# STM32L496ZGT7P register map
File version: 1.0
Registers are 32-bit, access not given, reset 0x0 unless marked. A register's access mark holds for its fields unless they carry their own. Offsets are from the block's base; [hi:lo] are bit positions; {n}, {i} and the like mark numbered series.

## OPAMP
Base 0x40007800
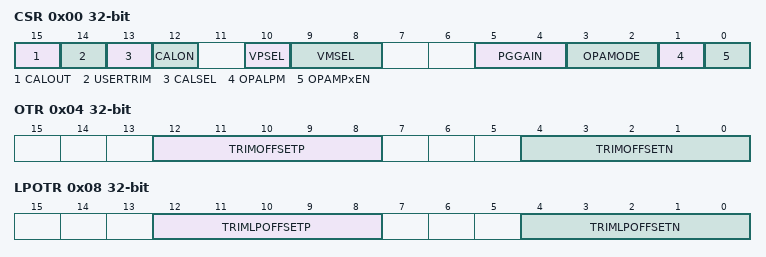
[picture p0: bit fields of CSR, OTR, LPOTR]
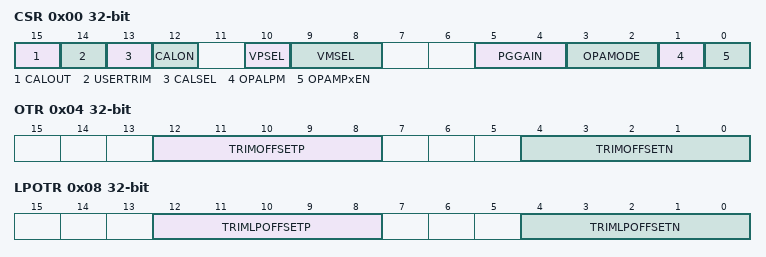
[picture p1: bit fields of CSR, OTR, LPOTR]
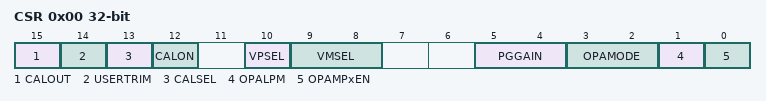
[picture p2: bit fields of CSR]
0x00 CSR
  [15] CALOUT, [14] USERTRIM, [13] CALSEL, [12] CALON, [10] VPSEL, [9:8] VMSEL, [5:4] PGGAIN, [3:2] OPAMODE, [1] OPALPM, [0] OPAMPxEN
0x04 OTR
  [12:8] TRIMOFFSETP, [4:0] TRIMOFFSETN
0x08 LPOTR
  [12:8] TRIMLPOFFSETP, [4:0] TRIMLPOFFSETN

## OPAMP1
Base 0x40007800
Same registers: OPAMP2 0x40007810
0x00 CSR
  [15] CALOUT, [14] USERTRIM, [13] CALSEL, [12] CALON, [10] VPSEL, [9:8] VMSEL, [5:4] PGGAIN, [3:2] OPAMODE, [1] OPALPM, [0] OPAMPxEN
0x04 OTR
  [12:8] TRIMOFFSETP, [4:0] TRIMOFFSETN
0x08 LPOTR
  [12:8] TRIMLPOFFSETP, [4:0] TRIMLPOFFSETN

## OPAMP12_COMMON
Base 0x40007800
0x00 CSR
  [15] CALOUT, [14] USERTRIM, [13] CALSEL, [12] CALON, [10] VPSEL, [9:8] VMSEL, [5:4] PGGAIN, [3:2] OPAMODE, [1] OPALPM, [0] OPAMPxEN

## LPTIM1
Base 0x40007C00
Same registers: LPTIM2 0x40009400
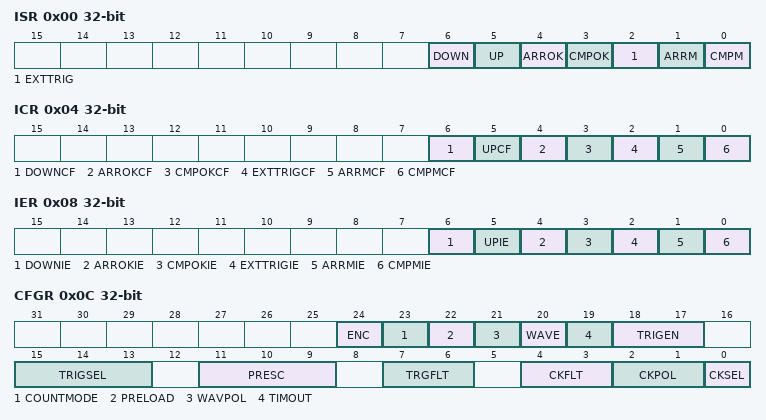
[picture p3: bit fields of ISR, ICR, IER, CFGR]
0x00 ISR
  [6] DOWN, [5] UP, [4] ARROK, [3] CMPOK, [2] EXTTRIG, [1] ARRM, [0] CMPM
0x04 ICR
  [6] DOWNCF, [5] UPCF, [4] ARROKCF, [3] CMPOKCF, [2] EXTTRIGCF, [1] ARRMCF, [0] CMPMCF
0x08 IER
  [6] DOWNIE, [5] UPIE, [4] ARROKIE, [3] CMPOKIE, [2] EXTTRIGIE, [1] ARRMIE, [0] CMPMIE
0x0C CFGR
  [24] ENC, [23] COUNTMODE, [22] PRELOAD, [21] WAVPOL, [20] WAVE, [19] TIMOUT, [18:17] TRIGEN, [15:13] TRIGSEL, [11:9] PRESC, [7:6] TRGFLT, [4:3] CKFLT, [2:1] CKPOL, [0] CKSEL
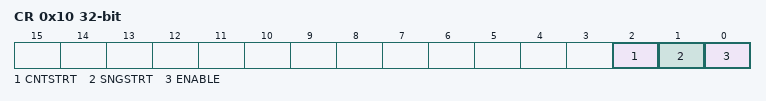
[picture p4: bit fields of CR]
0x10 CR
  [2] CNTSTRT, [1] SNGSTRT, [0] ENABLE
0x14 CMP
  [15:0] CMP
0x18 ARR
  [15:0] ARR
0x1C CNT
  [15:0] CNT
0x20 OR
  [1:0] OR

## SWPMI1
Base 0x40008800
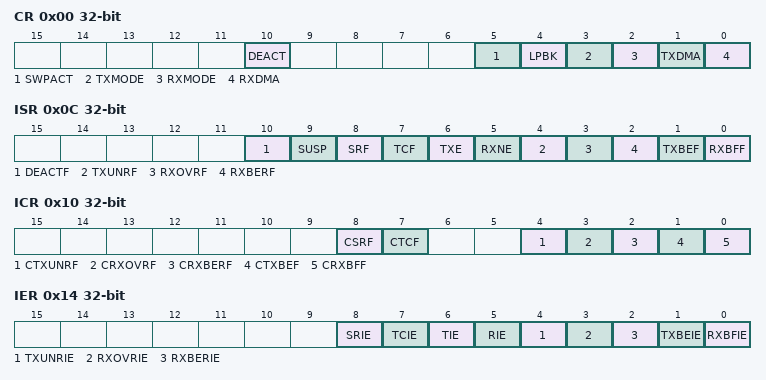
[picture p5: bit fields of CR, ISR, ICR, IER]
0x00 CR
  [10] DEACT, [5] SWPACT, [4] LPBK, [3] TXMODE, [2] RXMODE, [1] TXDMA, [0] RXDMA
0x04 BRR
  [5:0] BR
0x0C ISR
  [10] DEACTF, [9] SUSP, [8] SRF, [7] TCF, [6] TXE, [5] RXNE, [4] TXUNRF, [3] RXOVRF, [2] RXBERF, [1] TXBEF, [0] RXBFF
0x10 ICR
  [8] CSRF, [7] CTCF, [4] CTXUNRF, [3] CRXOVRF, [2] CRXBERF, [1] CTXBEF, [0] CRXBFF
0x14 IER
  [8] SRIE, [7] TCIE, [6] TIE, [5] RIE, [4] TXUNRIE, [3] RXOVRIE, [2] RXBERIE, [1] TXBEIE, [0] RXBFIE
0x18 RFL
  [1:0] RFL_0_1
0x1C TDR
  [31:0] TD
0x20 RDR
  [31:0] RD
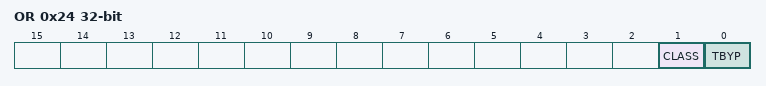
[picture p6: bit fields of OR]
0x24 OR
  [1] CLASS, [0] TBYP

## SYSCFG
Base 0x40010000
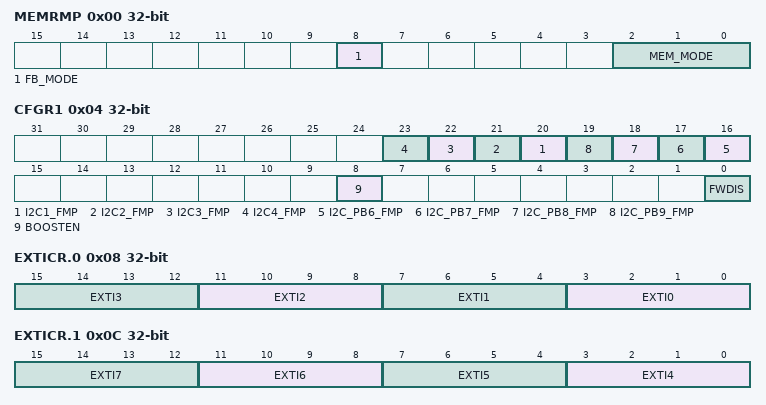
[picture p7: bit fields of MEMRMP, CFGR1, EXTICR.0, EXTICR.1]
0x00 MEMRMP
  [8] FB_MODE, [2:0] MEM_MODE
0x04 CFGR1
  [n+19] I2C{n}_FMP (n=1..4), [n+10] I2C_PB{n}_FMP (n=6..9), [8] BOOSTEN, [0] FWDIS
0x08 EXTICR.0
  [4n+3:4n] EXTI{n} (n=0..3)
0x0C EXTICR.1
  [4n-13:4n-16] EXTI{n} (n=4..7)
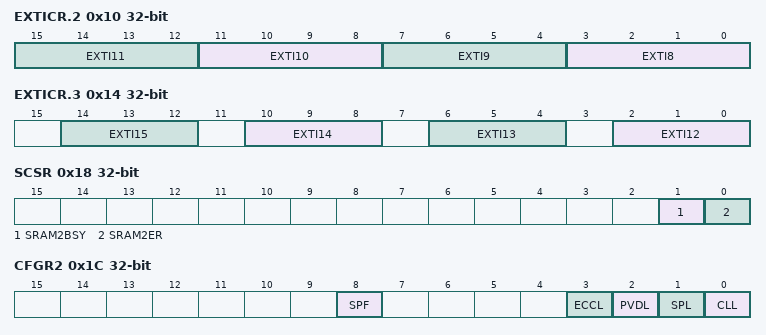
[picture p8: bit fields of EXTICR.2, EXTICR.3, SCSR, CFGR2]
0x10 EXTICR.2
  [4n-29:4n-32] EXTI{n} (n=8..11)
0x14 EXTICR.3
  [4n-46:4n-48] EXTI{n} (n=12..15)
0x18 SCSR
  [1] SRAM2BSY, [0] SRAM2ER
0x1C CFGR2
  [8] SPF, [3] ECCL, [2] PVDL, [1] SPL, [0] CLL
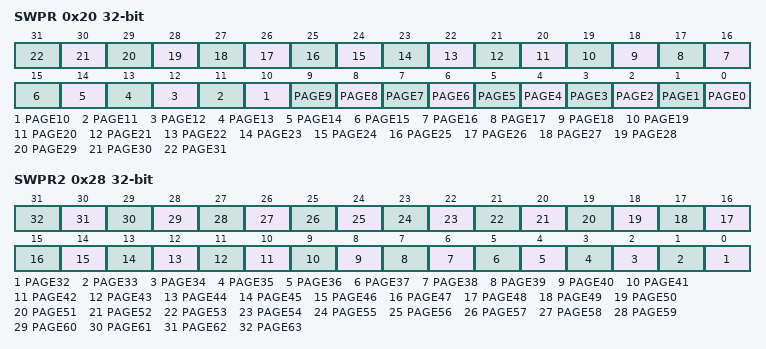
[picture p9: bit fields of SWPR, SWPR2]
0x20 SWPR
  [n] PAGE{n} (n=0..31)
0x24 SKR
  [7:0] KEY
0x28 SWPR2
  [n-32] PAGE{n} (n=32..63)

## VREFBUF
Base 0x40010030
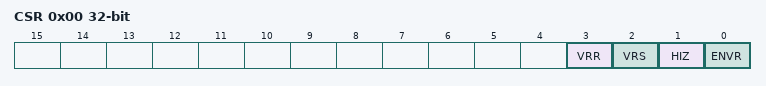
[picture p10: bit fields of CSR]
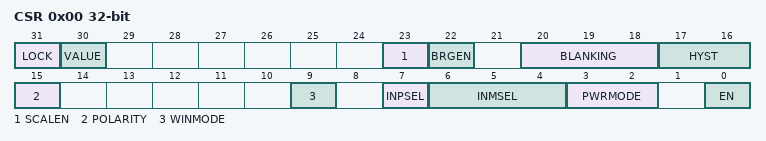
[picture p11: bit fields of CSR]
0x00 CSR
  [3] VRR, [2] VRS, [1] HIZ, [0] ENVR
0x04 CCR
  [5:0] TRIM

## COMP1
Base 0x40010200
Same registers: COMP2 0x40010204, COMP12_COMMON 0x40010204
0x00 CSR
  [31] LOCK, [30] VALUE, [23] SCALEN, [22] BRGEN, [20:18] BLANKING, [17:16] HYST, [15] POLARITY, [9] WINMODE, [7] INPSEL, [6:4] INMSEL, [3:2] PWRMODE, [0] EN

## EXTI
Base 0x40010400
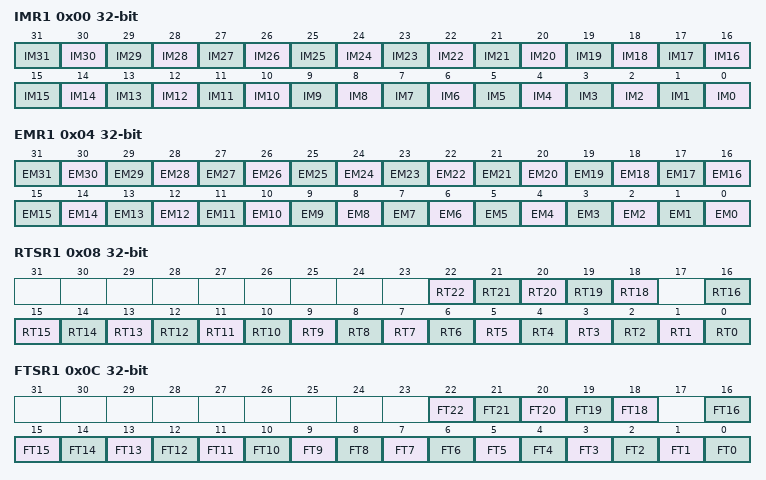
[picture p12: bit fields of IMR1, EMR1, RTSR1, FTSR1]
0x00 IMR1
  [n] IM{n} (n=0..31)
0x04 EMR1
  [n] EM{n} (n=0..31)
0x08 RTSR1
  [n] RT{n} (n=18..22), [n] RT{n} (n=0..16)
0x0C FTSR1
  [n] FT{n} (n=18..22), [n] FT{n} (n=0..16)
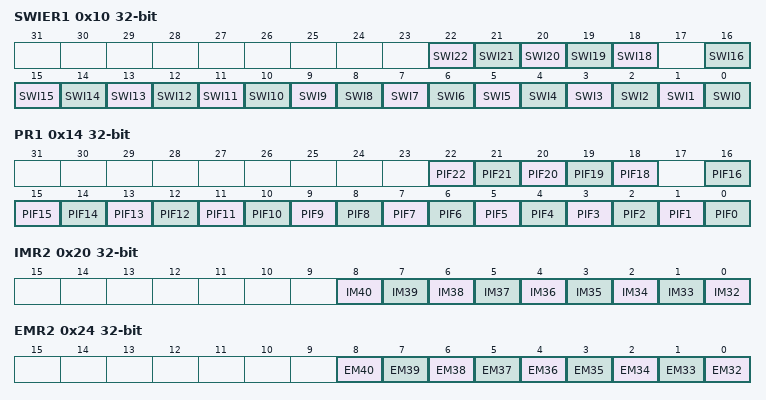
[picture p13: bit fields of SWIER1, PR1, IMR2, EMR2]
0x10 SWIER1
  [n] SWI{n} (n=18..22), [n] SWI{n} (n=0..16)
0x14 PR1
  [n] PIF{n} (n=18..22), [n] PIF{n} (n=0..16)
0x20 IMR2
  [n-32] IM{n} (n=32..40)
0x24 EMR2
  [n-32] EM{n} (n=32..40)
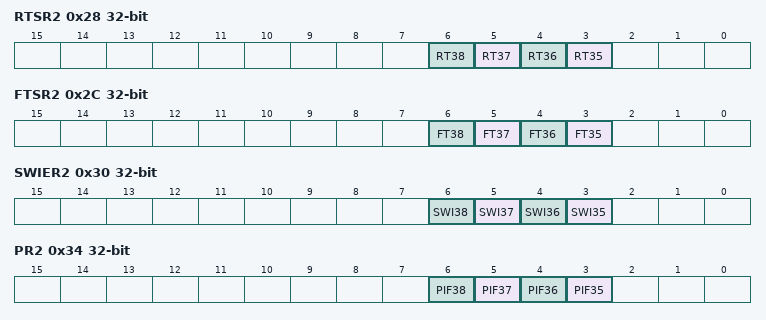
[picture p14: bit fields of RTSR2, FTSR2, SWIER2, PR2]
0x28 RTSR2
  [n-32] RT{n} (n=35..38)
0x2C FTSR2
  [n-32] FT{n} (n=35..38)
0x30 SWIER2
  [n-32] SWI{n} (n=35..38)
0x34 PR2
  [n-32] PIF{n} (n=35..38)

## FIREWALL
Base 0x40011C00
0x00 CSSA
0x04 CSL
0x08 NVDSSA
0x0C NVDSL
0x10 VDSSA
0x14 VDSL
0x20 CR

## SDMMC1
Base 0x40012800
0x00 POWER
  [1:0] PWRCTRL
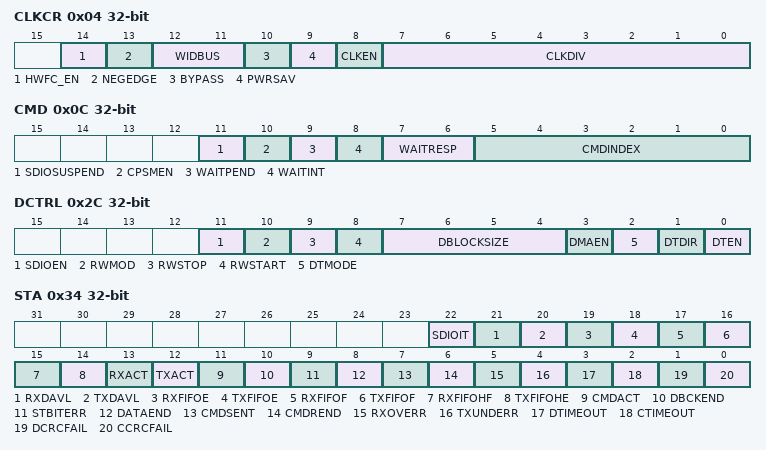
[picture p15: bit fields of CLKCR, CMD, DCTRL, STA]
0x04 CLKCR
  [14] HWFC_EN, [13] NEGEDGE, [12:11] WIDBUS, [10] BYPASS, [9] PWRSAV, [8] CLKEN, [7:0] CLKDIV
0x08 ARG
  [31:0] CMDARG
0x0C CMD
  [11] SDIOSUSPEND, [10] CPSMEN, [9] WAITPEND, [8] WAITINT, [7:6] WAITRESP, [5:0] CMDINDEX
0x10 RESPCMD
  [5:0] RESPCMD
{0x10+4i} RESP{i} (i=1..4)
  [31:0] CARDSTATUS{i}
0x24 DTIMER
  [31:0] DATATIME
0x28 DLEN
  [24:0] DATALENGTH
0x2C DCTRL
  [11] SDIOEN, [10] RWMOD, [9] RWSTOP, [8] RWSTART, [7:4] DBLOCKSIZE, [3] DMAEN, [2] DTMODE, [1] DTDIR, [0] DTEN
0x30 DCOUNT
  [24:0] DATACOUNT
0x34 STA
  [22] SDIOIT, [21] RXDAVL, [20] TXDAVL, [19] RXFIFOE, [18] TXFIFOE, [17] RXFIFOF, [16] TXFIFOF, [15] RXFIFOHF, [14] TXFIFOHE, [13] RXACT, [12] TXACT, [11] CMDACT, [10] DBCKEND, [9] STBITERR, [8] DATAEND, [7] CMDSENT, [6] CMDREND, [5] RXOVERR, [4] TXUNDERR, [3] DTIMEOUT, [2] CTIMEOUT, [1] DCRCFAIL, [0] CCRCFAIL
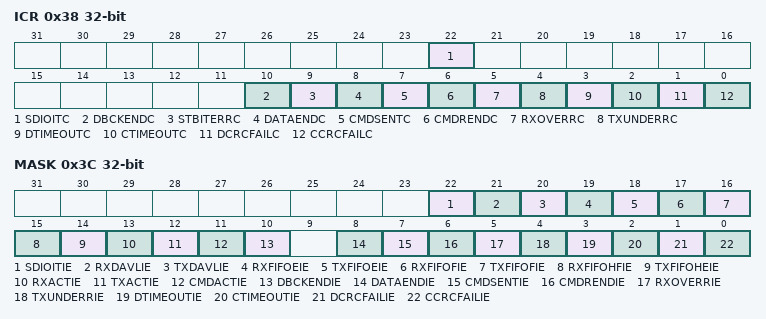
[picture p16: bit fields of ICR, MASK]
0x38 ICR
  [22] SDIOITC, [10] DBCKENDC, [9] STBITERRC, [8] DATAENDC, [7] CMDSENTC, [6] CMDRENDC, [5] RXOVERRC, [4] TXUNDERRC, [3] DTIMEOUTC, [2] CTIMEOUTC, [1] DCRCFAILC, [0] CCRCFAILC
0x3C MASK
  [22] SDIOITIE, [21] RXDAVLIE, [20] TXDAVLIE, [19] RXFIFOEIE, [18] TXFIFOEIE, [17] RXFIFOFIE, [16] TXFIFOFIE, [15] RXFIFOHFIE, [14] TXFIFOHEIE, [13] RXACTIE, [12] TXACTIE, [11] CMDACTIE, [10] DBCKENDIE, [8] DATAENDIE, [7] CMDSENTIE, [6] CMDRENDIE, [5] RXOVERRIE, [4] TXUNDERRIE, [3] DTIMEOUTIE, [2] CTIMEOUTIE, [1] DCRCFAILIE, [0] CCRCFAILIE
0x48 FIFOCNT
  [23:0] FIFOCOUNT
0x80 FIFO
  [31:0] FIFODATA
